# STM32H533 register map
File version: 1.3
CPU: CM33 r0p0, little endian, MPU, FPU, 4 interrupt priority bits
Registers are 32-bit, read-write, reset 0x0 unless marked. A register's access mark holds for its fields unless they carry their own. Offsets are from the block's base; [hi:lo] are bit positions; {n}, {i} and the like mark numbered series; 'fields as' and 'values as' point back to an identical list.

## EXTI — EXTI address block description
Base 0x44022000
Same registers: EXTI_S 0x54022000
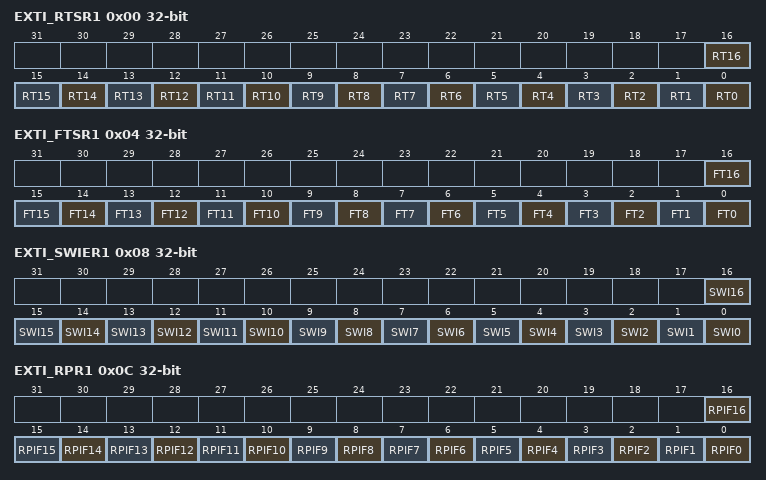
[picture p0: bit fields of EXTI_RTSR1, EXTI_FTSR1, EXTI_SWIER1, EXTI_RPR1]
0x00 EXTI_RTSR1 — EXTI rising trigger selection register
  [all] fields
    0=Rising trigger disabled (for event and interrupt) for input line; 1=Rising trigger enabled (for event and interrupt) for input line
  [n] RT{n} (n=0..16) — Rising trigger event configuration bit of configurable event input x
0x04 EXTI_FTSR1 — EXTI falling trigger selection register
  [all] fields
    0=Falling trigger disabled (for event and Interrupt) for input line; 1=Falling trigger enabled (for event and Interrupt) for input line
  [n] FT{n} (n=0..16) — Falling trigger event configuration bit of configurable event input x
0x08 EXTI_SWIER1 — EXTI software interrupt event register
  [all] fields
    0=Writing 0 has no effect; 1=Writing 1 triggers a rising edge event on event x
  [n] SWI{n} (n=0..16) — Software interrupt on event x
0x0C EXTI_RPR1 — EXTI rising edge pending register
  [all] fields
    0=No rising edge trigger request occurred; 1=Rising edge trigger request occurred
  [n] RPIF{n} (n=0..16) — configurable event inputs x rising edge pending bit
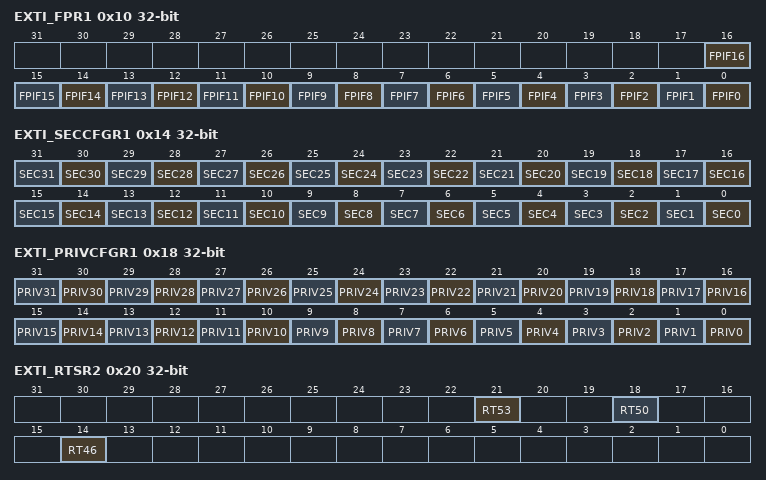
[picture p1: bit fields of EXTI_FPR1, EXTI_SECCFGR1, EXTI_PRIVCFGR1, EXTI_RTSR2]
0x10 EXTI_FPR1 — EXTI falling edge pending register
  [all] fields
    0=No falling edge trigger request occurred; 1=Falling edge trigger request occurred
  [n] FPIF{n} (n=0..16) — configurable event inputs x falling edge pending bit
0x14 EXTI_SECCFGR1 — EXTI security configuration register
  [all] fields
    0=Event security disabled (non-secure); 1=Event security enabled (secure)
  [n] SEC{n} (n=0..31) — Security enable on event input x
0x18 EXTI_PRIVCFGR1 — EXTI privilege configuration register
  [all] fields
    0=Event privilege disabled (unprivileged); 1=Event privilege enabled (privileged)
  [n] PRIV{n} (n=0..31) — Security enable on event input x
0x20 EXTI_RTSR2 — EXTI rising trigger selection register 2
  [all] fields
    values as the fields of EXTI_RTSR1
  [21] RT53 — Rising trigger event configuration bit of configurable event input x
  [18] RT50 — Rising trigger event configuration bit of configurable event input xless thansup>(1)less than/sup>
  [14] RT46 — Rising trigger event configuration bit of configurable event input xless thansup>(1)less than/sup>
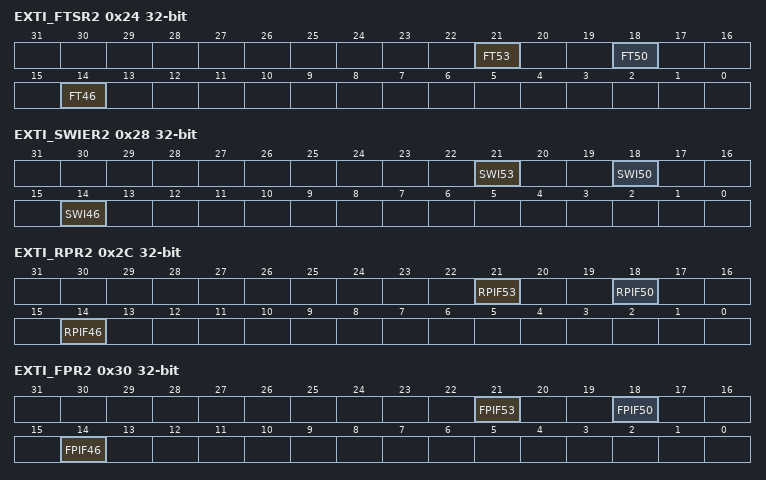
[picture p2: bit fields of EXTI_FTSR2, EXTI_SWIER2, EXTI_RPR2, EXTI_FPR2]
0x24 EXTI_FTSR2 — EXTI falling trigger selection register 2
  [all] fields
    values as the fields of EXTI_FTSR1
  [21] FT53 — Falling trigger event configuration bit of configurable event input x
  [18] FT50 — Falling trigger event configuration bit of configurable event input x less thansup>(1)less than/sup>
  [14] FT46 — Falling trigger event configuration bit of configurable event input x less thansup>(1)less than/sup>
0x28 EXTI_SWIER2 — EXTI software interrupt event register 2
  [all] fields
    values as the fields of EXTI_SWIER1
  [21] SWI53 — Software interrupt on event x
  [18] SWI50 — Software interrupt on event x
  [14] SWI46 — Software interrupt on event x
0x2C EXTI_RPR2 — EXTI rising edge pending register 2
  [all] fields
    values as the fields of EXTI_RPR1
  [21] RPIF53 — configurable event inputs x rising edge pending bit
  [18] RPIF50 — configurable event inputs x rising edge pending bit
  [14] RPIF46 — configurable event inputs x rising edge pending bit
0x30 EXTI_FPR2 — EXTI falling edge pending register 2
  [all] fields
    values as the fields of EXTI_FPR1
  [21] FPIF53 — configurable event inputs x falling edge pending bit
  [18] FPIF50 — configurable event inputs x falling edge pending bit
  [14] FPIF46 — configurable event inputs x falling edge pending bit
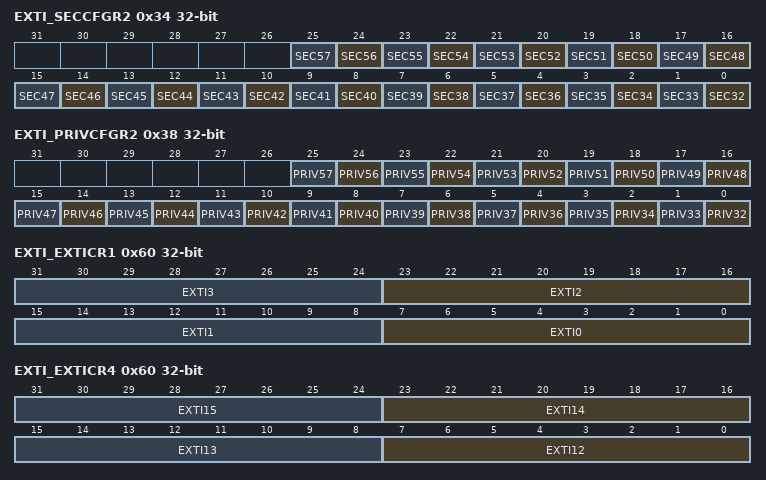
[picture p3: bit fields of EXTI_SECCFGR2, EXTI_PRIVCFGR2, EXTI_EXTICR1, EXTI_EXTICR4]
0x34 EXTI_SECCFGR2 — EXTI security configuration register 2
  [all] fields
    values as the fields of EXTI_SECCFGR1
  [n-32] SEC{n} (n=32..57) — Security enable on event input x
0x38 EXTI_PRIVCFGR2 — EXTI privilege configuration register 2
  [all] fields
    values as the fields of EXTI_PRIVCFGR1
  [n-32] PRIV{n} (n=32..57) — Security enable on event input x
0x60 EXTI_EXTICR1 — EXTI external interrupt selection register
  [8n+7:8n] EXTI{n} (n=0..3) — EXTI{n} GPIO port selection
    0=PA{n} pin; 1=PB{n} pin; 2=PC{n} pin; 3=PD{n} pin; 4=PE{n} pin; 5=PF{n} pin; 6=PG{n} pin; 7=PH{n} pin; 8=PI{n} pin
0x60 EXTI_EXTICR4 (alternate view of EXTI_EXTICR1) — EXTI external interrupt selection register
  [8n-89:8n-96] EXTI{n} (n=12..15) — EXTI{n} GPIO port selection
    0=PA{n} pin; 1=PB{n} pin; 2=PC{n} pin; 3=PD{n} pin; 4=PE{n} pin; 5=PF{n} pin; 6=PG{n} pin; 7=PH{n} pin
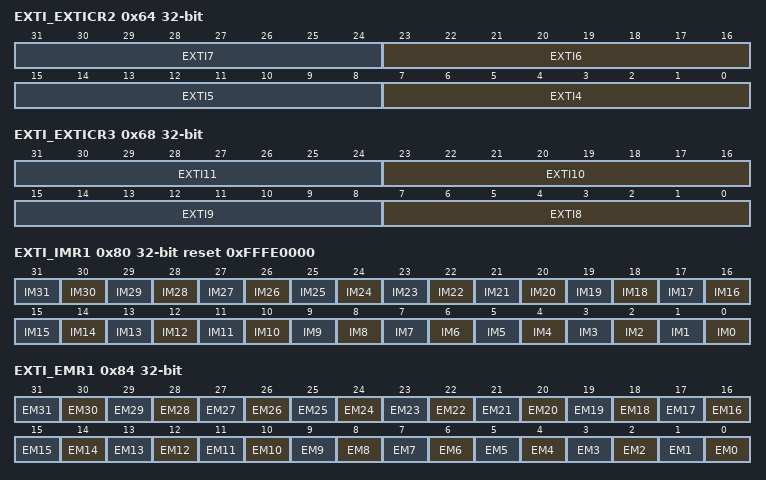
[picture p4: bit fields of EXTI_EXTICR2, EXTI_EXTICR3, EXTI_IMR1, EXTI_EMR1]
0x64 EXTI_EXTICR2 — EXTI external interrupt selection register
  [8n-25:8n-32] EXTI{n} (n=4..7) — EXTI{n} GPIO port selection
    values as EXTI_EXTICR1.EXTI0
0x68 EXTI_EXTICR3 — EXTI external interrupt selection register
  [8n-57:8n-64] EXTI{n} (n=8..11) — EXTI{n} GPIO port selection
    values as EXTI_EXTICR1.EXTI0
0x70 EXTI_LOCKR — EXTI lock register
  [0] LOCK — Global security and privilege configuration registers (EXTI_SECCFGR and EXTI_PRIVCFGR) lock
    0=Security and privilege configuration open, can be modified; 1=Security and privilege configuration locked, can no longer be modified
0x80 EXTI_IMR1 reset 0xFFFE0000 — EXTI CPU wake-up with interrupt mask register
  [all] fields
    0=Wake-up with interrupt request from input event x is masked; 1=Wake-up with interrupt request from input event x is unmasked
  [n] IM{n} (n=0..31) — CPU wake-up with interrupt mask on event input x
0x84 EXTI_EMR1 — EXTI CPU wake-up with event mask register
  [all] fields
    0=Wake-up with event generation from Line x is masked; 1=Wake-up with event generation from Line x is unmasked
  [n] EM{n} (n=0..31) — CPU wake-up with event generation mask on event input x
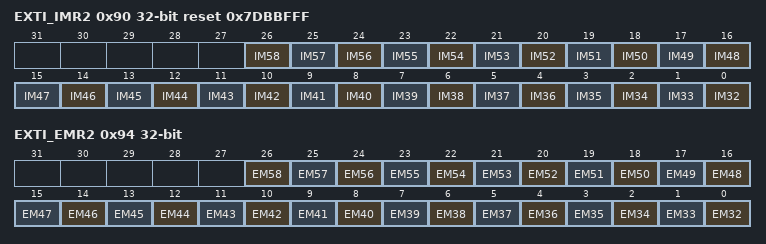
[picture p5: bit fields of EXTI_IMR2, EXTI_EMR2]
0x90 EXTI_IMR2 reset 0x7DBBFFF — EXTI CPU wake-up with interrupt mask register 2
  [all] fields
    values as the fields of EXTI_IMR1
  [n-32] IM{n} (n=32..58) — CPU wake-up with interrupt mask on event input x
0x94 EXTI_EMR2 — EXTI CPU wake-up with event mask register 2
  [all] fields
    values as the fields of EXTI_EMR1
  [n-32] EM{n} (n=32..58) — CPU wake-up with event generation mask on event input x
